# cc13x2_cc26x2 register map
File version: 2.1
CPU: CM4 r0p1, little endian, MPU, FPU, 3 interrupt priority bits
Registers are 32-bit, read-write, reset 0x0 unless marked. A register's access mark holds for its fields unless they carry their own. Offsets are from the block's base; [hi:lo] are bit positions; {n}, {i} and the like mark numbered series.

## GPT0 — General Purpose Timer.
Base 0x40010000
Same registers: GPT1 0x40011000, GPT2 0x40012000, GPT3 0x40013000
0x00 CFG — Configuration
  [2:0] CFG
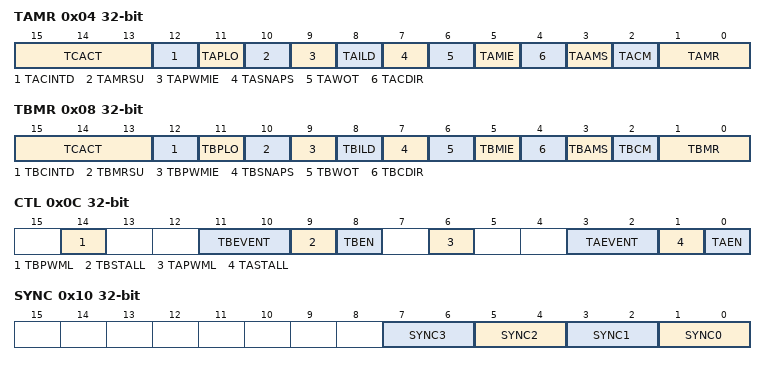
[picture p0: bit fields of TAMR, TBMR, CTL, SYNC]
0x04 TAMR — Timer A Mode
  [15:13] TCACT, [12] TACINTD, [11] TAPLO, [10] TAMRSU, [9] TAPWMIE, [8] TAILD, [7] TASNAPS, [6] TAWOT, [5] TAMIE, [4] TACDIR, [3] TAAMS, [2] TACM, [1:0] TAMR
0x08 TBMR — Timer B Mode
  [15:13] TCACT, [12] TBCINTD, [11] TBPLO, [10] TBMRSU, [9] TBPWMIE, [8] TBILD, [7] TBSNAPS, [6] TBWOT, [5] TBMIE, [4] TBCDIR, [3] TBAMS, [2] TBCM, [1:0] TBMR
0x0C CTL — Control
  [14] TBPWML, [11:10] TBEVENT, [9] TBSTALL, [8] TBEN, [6] TAPWML, [3:2] TAEVENT, [1] TASTALL, [0] TAEN
0x10 SYNC — Synch Register
  [2n+1:2n] SYNC{n} (n=0..3)
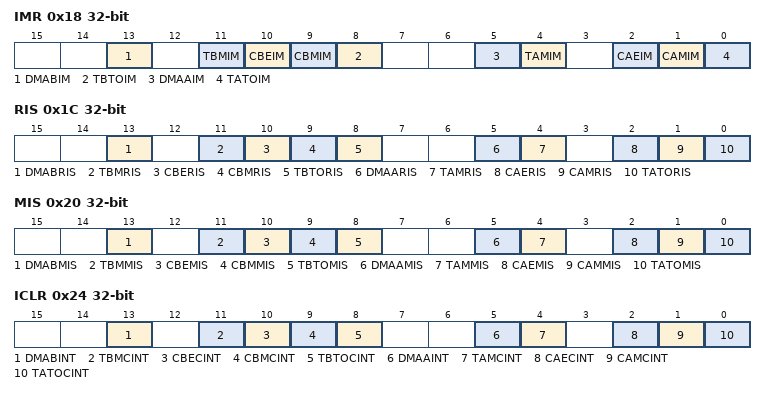
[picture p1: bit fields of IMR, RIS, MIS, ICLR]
0x18 IMR — Interrupt Mask his register is used to enable the interrupts. ssociated registers: IS, MIS, ICLR
  [13] DMABIM, [11] TBMIM, [10] CBEIM, [9] CBMIM, [8] TBTOIM, [5] DMAAIM, [4] TAMIM, [2] CAEIM, [1] CAMIM, [0] TATOIM
0x1C RIS ro — Raw Interrupt Status ssociated registers: MR, MIS, ICLR
  [13] DMABRIS, [11] TBMRIS, [10] CBERIS, [9] CBMRIS, [8] TBTORIS, [5] DMAARIS, [4] TAMRIS, [2] CAERIS, [1] CAMRIS, [0] TATORIS
0x20 MIS ro — Masked Interrupt Status alues are result of bitwise AND operation between RIS and IMR ssosciated clear register: ICLR
  [13] DMABMIS, [11] TBMMIS, [10] CBEMIS, [9] CBMMIS, [8] TBTOMIS, [5] DMAAMIS, [4] TAMMIS, [2] CAEMIS, [1] CAMMIS, [0] TATOMIS
0x24 ICLR — Interrupt Clear his register is used to clear status bits in the RIS and MIS registers
  [13] DMABINT write-1-clears, [11] TBMCINT write-1-clears, [10] CBECINT write-1-clears, [9] CBMCINT write-1-clears, [8] TBTOCINT write-1-clears, [5] DMAAINT write-1-clears, [4] TAMCINT write-1-clears, [2] CAECINT write-1-clears, [1] CAMCINT write-1-clears, [0] TATOCINT write-1-clears
0x28 TAILR reset 0xFFFFFFFF — Timer A Interval Load Register
0x2C TBILR reset 0xFFFF — Timer B Interval Load Register
0x30 TAMATCHR reset 0xFFFFFFFF — Timer A Match Register nterrupts can be generated when the timer value is equal to the value in this register in one-shot or periodic mode. n Edge-Count mode, this register along with TAILR, determines how many edge events are counted. he total number of edge events counted is equal to the value in TAILR minus this value. ote that in edge-count mode, when executing an up-count, the value of TAPR and TAILR must be greater than the value of TAPMR and this register. n PWM mode, this value along with TAILR, determines the duty cycle of the output PWM signal. hen a 16/32-bit GPT is configured to one of the 32-bit modes, TAMATCHR appears as a 32-bit register. (The upper 16-bits correspond to the contents TBMATCHR). n a 16-bit mode, the upper 16 bits of this register read as 0s and have no effect on the state of TBMATCHR. ote : This register is updated internally (takes effect) based on TAMR.TAMRSU
0x34 TBMATCHR reset 0xFFFF — Timer B Match Register When a GPT is configured to one of the 32-bit modes, the contents of bits 15:0 in this register are loaded into the upper 16 bits of TAMATCHR. eads from this register return the current match value of Timer B and writes are ignored. n a 16-bit mode, bits 15:0 are used for the match value. Bits 31:16 are reserved in both cases. ote : This register is updated internally (takes effect) based on TBMR.TBMRSU
  [15:0] TBMATCHR
0x38 TAPR — Timer A Pre-scale his register allows software to extend the range of the timers when they are used individually. hen in one-shot or periodic down count modes, this register acts as a true prescaler for the timer counter. hen acting as a true prescaler, the prescaler counts down to 0 before the value in TAR and TAV registers are incremented. n all other individual/split modes, this register is a linear extension of the upper range of the timer counter, holding bits 23:16 in the 16-bit modes of the 16/32-bit GPT.
  [7:0] TAPSR
0x3C TBPR — Timer B Pre-scale his register allows software to extend the range of the timers when they are used individually. hen in one-shot or periodic down count modes, this register acts as a true prescaler for the timer counter. hen acting as a true prescaler, the prescaler counts down to 0 before the value in TBR and TBV registers are incremented. n all other individual/split modes, this register is a linear extension of the upper range of the timer counter, holding bits 23:16 in the 16-bit modes of the 16/32-bit GPT.
  [7:0] TBPSR
0x40 TAPMR — Timer A Pre-scale Match his register allows software to extend the range of the TAMATCHR when used individually.
  [7:0] TAPSMR
0x44 TBPMR — Timer B Pre-scale Match his register allows software to extend the range of the TBMATCHR when used individually.
  [7:0] TBPSMR
0x48 TAR ro reset 0xFFFFFFFF — Timer A Register his register shows the current value of the Timer A counter in all cases except for Input Edge Count and Time modes. In the Input Edge Count mode, this register contains the number of edges that ave occurred. In the Input Edge Time mode, this register contains the time at which the last edge event took place. hen a GPT is configured to one of the 32-bit modes, this register appears as a 32-bit register (the upper 16-bits correspond to the contents of the Timer B (TBR) register). In he16-bit Input Edge Count, Input Edge Time, and PWM modes, bits 15:0 contain the value of the counter and bits 23:16 contain the value of the prescaler, which is the upper 8 bits of the count. Bits 1:24 always read as 0. To read the value of the prescaler in 16-bit One-Shot and Periodic modes, read bits [23:16] in the TAV register. To read the value of the prescalar in periodic snapshot ode, read the Timer A Prescale Snapshot (TAPS) register.
0x4C TBR ro reset 0xFFFF — Timer B Register his register shows the current value of the Timer B counter in all cases except for Input Edge Count and Time modes. In the Input Edge Count mode, this register contains the number of edges that ave occurred. In the Input Edge Time mode, this register contains the time at which the last edge event took place. hen a GPTM is configured to one of the 32-bit modes, the contents of bits 15:0 in this register are loaded into the upper 16 bits of the TAR register. Reads from this register return the current alue of Timer B. In a 16-bit mode, bits 15:0 contain the value of the counter and bits 23:16 contain the value of the prescaler in Input Edge Count, Input Edge Time, and PWM modes, which is the pper 8 bits of the count. Bits 31:24 always read as 0. To read the value of the prescaler in 16-bit One-Shot and Periodic modes, read bits [23:16] in the TBV register. To read the value of the rescalar in periodic snapshot mode, read the Timer B Prescale Snapshot (TBPS) register.
0x50 TAV reset 0xFFFFFFFF — Timer A Value hen read, this register shows the current, free-running value of Timer A in all modes. Softwarecan use this value to determine the time elapsed between an interrupt and the ISR entry when using he snapshot feature with the periodic operating mode. When written, the value written into this register is loaded into the TAR register on the next clock cycle. hen a 16/32-bit GPTM is configured to one of the 32-bit modes, this register appears as a 32-bit register (the upper 16-bits correspond to the contents of the GPTM Timer B Value (TBV) register). In a 16-bit mode, bits 15:0 contain the value of the counter and bits 23:16 contain the current, free-running value of the prescaler, which is the upper 8 bits of the count in Input Edge Count, Input Edge Time, PWM and one-shot or periodic up count modes. In one-shot or periodic own count modes, the prescaler stored in 23:16 is a true prescaler, meaning bits 23:16 count down before decrementing the value in bits 15:0. The prescaler in bits 31:24 always reads as 0.
0x54 TBV reset 0xFFFF — Timer B Value hen read, this register shows the current, free-running value of Timer B in all modes. Software can use this value to determine the time elapsed between an interrupt and the ISR entry. When ritten, the value written into this register is loaded into the TBR register on the next clock cycle. hen a 16/32-bit GPTM is configured to one of the 32-bit modes, the contents of bits 15:0 in this register are loaded into the upper 16 bits of the TAV register. Reads from this register return he current free-running value of Timer B. In a 16-bit mode, bits 15:0 contain the value of the counter and bits 23:16 contain the current, free-running value of the prescaler, which is the upper 8 bits of he count in Input Edge Count, Input Edge Time, PWM and one-shot or periodic up count modes. n one-shot or periodic down count modes, the prescaler stored in 23:16 is a true prescaler, meaning bits 23:16 count down before decrementing the value in bits 15:0. The prescaler in bits 31:24 always reads as 0.
0x5C TAPS ro — Timer A Pre-scale Snap-shot ased on the value in the register field TAMR.TAILD, this register is updated with the value from TAPR register either on the next cycle or on the next timeout. his register shows the current value of the Timer A pre-scaler in the 16-bit mode.
  [7:0] PSS
0x60 TBPS ro — Timer B Pre-scale Snap-shot ased on the value in the register field TBMR.TBILD, this register is updated with the value from TBPR register either on the next cycle or on the next timeout. his register shows the current value of the Timer B pre-scaler in the 16-bit mode.
  [7:0] PSS
0x64 TAPV ro — Timer A Pre-scale Value his register shows the current value of the Timer A free running pre-scaler in the 16-bit mode.
  [7:0] PSV
0x68 TBPV ro — Timer B Pre-scale Value his register shows the current value of the Timer B free running pre-scaler in the 16-bit mode.
  [7:0] PSV
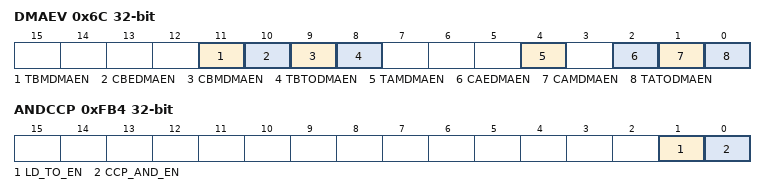
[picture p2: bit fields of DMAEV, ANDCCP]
0x6C DMAEV — DMA Event his register allows software to enable/disable GPT DMA trigger events.
  [11] TBMDMAEN, [10] CBEDMAEN, [9] CBMDMAEN, [8] TBTODMAEN, [4] TAMDMAEN, [2] CAEDMAEN, [1] CAMDMAEN, [0] TATODMAEN
0xFB0 VERSION ro reset 0x400 — Peripheral Version his register provides information regarding the GPT version
0xFB4 ANDCCP — Combined CCP Output his register is used to logically AND CCP output pairs for each timer
  [1] LD_TO_EN, [0] CCP_AND_EN
